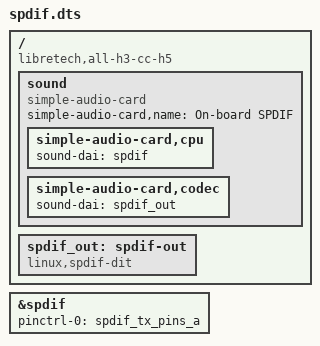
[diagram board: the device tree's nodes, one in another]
// SPDX-License-Identifier: (GPL-2.0+ OR MIT)
/*
 * Copyright (c) 2023 Da Xue <da@libre.computer>
 * Author: Da Xue <da@libre.computer>
 */

/* 40P GPIO
 * Pin 26
 */

/dts-v1/;
/plugin/;

/ {
	compatible = "libretech,all-h3-cc-h5", "libretech,all-h3-cc-h3", "allwinner,sun50i-h5", "allwinner,sun8i-h3";

	fragment@0 {
		target = <&spdif>;
		__overlay__ {
			pinctrl-names = "default";
			pinctrl-0 = <&spdif_tx_pins_a>;
			status = "okay";
		};
	};

	fragment@1 {
		target-path = "/";
		__overlay__ {
			sound {
				compatible = "simple-audio-card";
				simple-audio-card,name = "On-board SPDIF";

				simple-audio-card,cpu {
					sound-dai = <&spdif>;
				};

				simple-audio-card,codec {
					sound-dai = <&spdif_out>;
				};
			};

			spdif_out: spdif-out {
				#sound-dai-cells = <0>;
				compatible = "linux,spdif-dit";
			};
		};
	};
};
